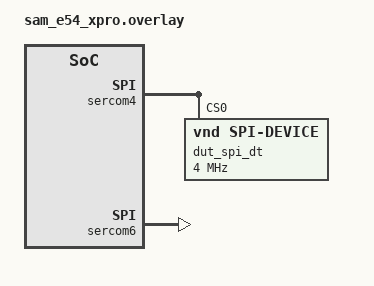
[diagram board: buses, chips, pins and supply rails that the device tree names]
/*
 * Copyright (c) 2025 Microchip Technology Inc.
 *
 * SPDX-License-Identifier: Apache-2.0
 */

&sercom4 {
	status = "okay";
	compatible = "microchip,sercom-g1-spi";
	dipo = <3>;
	dopo = <0>;
	#address-cells = <1>;
	#size-cells = <0>;
	pinctrl-0 = <&sercom4_spi_default>;
	pinctrl-names = "default";
	dut_spi_dt: test-spi-dev@0 {
		compatible = "vnd,spi-device";
		reg = <0>;
		spi-max-frequency = <4000000>;
	};
};

dut_spis: &sercom6 {
	status = "okay";
	dipo = <0>;
	dopo = <2>;
};

&pinctrl {
	sercom4_spi_default: sercom4_spi_default {
		group1 {
			pinmux = <PB27D_SERCOM4_PAD0>,
					 <PB29D_SERCOM4_PAD3>,
					 <PB26D_SERCOM4_PAD1>,
					 <PB28D_SERCOM4_PAD2>;
		};
	};
};
